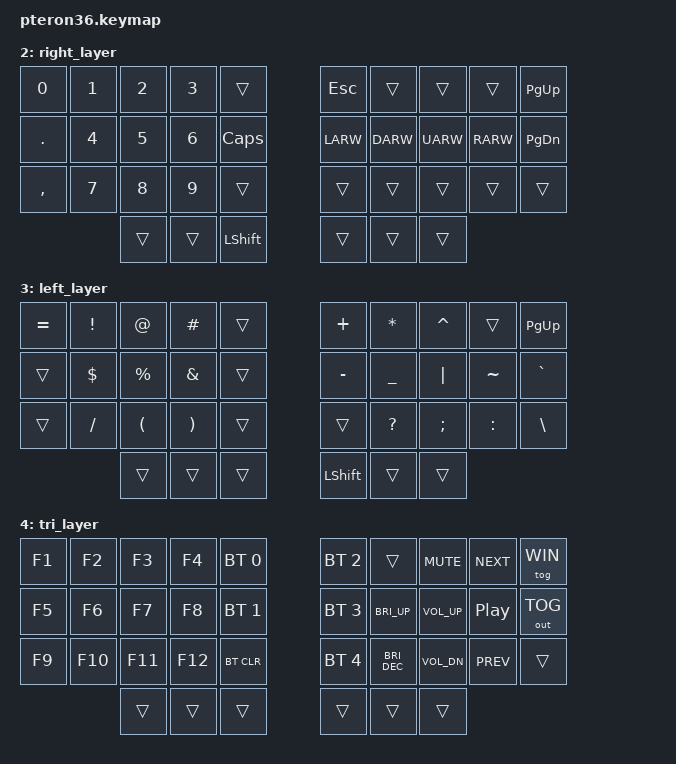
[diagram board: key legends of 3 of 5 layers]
#include <behaviors.dtsi>
#include <dt-bindings/zmk/keys.h>
#include <dt-bindings/zmk/bt.h>
#include <dt-bindings/zmk/outputs.h>

//Home row mods macros
#define HRML(k1,k2,k3,k4) &ht LALT k1 &ht LCTRL k2 &ht LGUI k3 &ht LSHFT k4
#define HRMR(k1,k2,k3,k4) &ht LSHFT k1 &ht LGUI k2 &ht LCTRL k3 &ht LALT k4
#define WRML(k1,k2,k3,k4) &ht LALT k1 &ht LCTRL k2 &ht LGUI k3 &ht LSHFT k4
#define WRMR(k1,k2,k3,k4) &ht LSHFT k1 &ht LGUI k2 &ht LCTRL k3 &ht LALT k4

#define MAC 0
#define WIN 1
#define RIG 2
#define LEF 3
#define TRI 4

/ {
    behaviors {
        ht: hold_tap {
            label = "hold_tap";
            compatible = "zmk,behavior-hold-tap";
            #binding-cells = <2>;
            flavor = "tap-preferred";
            tapping-term-ms = <220>;
            quick-tap-ms = <150>;
            global-quick-tap;
            bindings = <&kp>, <&kp>;
        };
    };

    conditional_layers {
        compatible = "zmk,conditional-layers";
        tri_layer {
            if-layers = < RIG LEF>;
            then-layer = <TRI>;
        };
    };

    combos {
        compatible = "zmk,combos";
        combo {
            timeout-ms = <50>;
            key-positions = < 6 7 8 >;
            bindings = <&kp RET>;
        };
    };

    keymap {
        compatible = "zmk,keymap";
        default_layer {
            bindings = <
                &kp Q &kp W &kp E &kp R       &kp T                                   &kp Y &kp U &kp I       &kp O     &kp P
                HRML(A,   S,    D,    F)      &kp G                                   &kp H HRMR(J,   K,          L,        LBKT)
                &kp Z &kp X &kp C &kp V       &kp B                                   &kp N &kp M &kp SQT   &kp SEMI   &kp RBKT
                                  
                                              &kp BSPC &lt LEF TAB &kp DEL      &trans &lt RIG DEL &kp SPACE
            >;
        };

        windows_layer{
            bindings = <
                &kp Q &kp W &kp E &kp R       &kp T                                   &kp Y &kp U &kp I       &kp O     &kp P
                HRML(A,   S,    D,    F)      &kp G                                   &kp H HRMR(J,   K,          L,        LBKT)
                &kp Z &kp X &kp C &kp V       &kp B                                   &kp N &kp M &kp SQT   &kp SEMI   &kp RBKT
                                  
                                              &kp BSPC &lt LEF TAB &kp DEL      &trans &lt RIG DEL &kp SPACE
            >;
        };

        right_layer{                
            bindings = <
                &kp N0  &kp N1 &kp N2 &kp N3  &trans                                  &kp ESC   &trans   &trans   &trans   &kp PG_UP
                &kp DOT  &kp N4 &kp N5 &kp N6  &kp CAPS                                &kp LARW &kp DARW &kp UARW &kp RARW &kp PG_DN   
                &kp COMMA  &kp N7 &kp N8 &kp N9  &trans                                  &trans   &trans   &trans   &trans   &trans
                                  
                                              &trans &trans &kp LSHFT      &trans &trans &trans
            >;
        };

        left_layer{
            bindings = <
                &kp EQUAL     &kp EXCL  &kp AT    &kp HASH  &trans                            &kp PLUS   &kp ASTRK  &kp CARET &trans      &kp PG_UP
                &trans       &kp DLLR  &kp PRCNT &kp AMPS  &trans                             &kp MINUS  &kp UNDER  &kp PIPE  &kp TILDE   &kp GRAVE  
                &trans       &kp FSLH  &kp LPAR  &kp RPAR  &trans                             &trans   &kp QMARK  &kp SEMI  &kp COLON   &kp BSLH
                                  
                                              &trans &trans &trans             &kp LSHFT &trans &trans
            >;
        };

        tri_layer{
            bindings = <
                &kp F1     &kp F2  &kp F3    &kp F4   &bt BT_SEL 0                         &bt BT_SEL 2  &trans         &kp C_MUTE    &kp C_NEXT  &tog WIN
                &kp F5     &kp F6  &kp F7    &kp F8   &bt BT_SEL 1                         &bt BT_SEL 3  &kp C_BRI_UP   &kp C_VOL_UP  &kp C_PP    &out OUT_TOG  
                &kp F9     &kp F10  &kp F11  &kp F12  &bt BT_CLR                           &bt BT_SEL 4  &kp C_BRI_DEC  &kp C_VOL_DN  &kp C_PREV  &trans
                                  
                                                      &trans &trans &trans      &trans &trans &trans
            >;
        };

    };
};  
